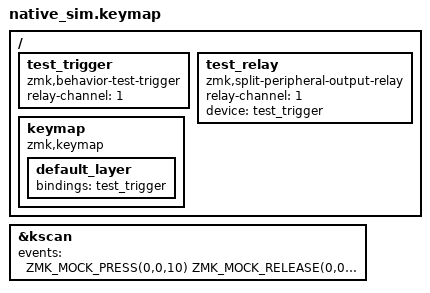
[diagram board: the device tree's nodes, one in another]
#include <dt-bindings/zmk/keys.h>
#include <behaviors.dtsi>
#include <dt-bindings/zmk/kscan_mock.h>

/ {
    test_trigger: test_trigger {
        compatible = "zmk,behavior-test-trigger";
        #binding-cells = <0>;
        relay-channel = <1>;
    };

    test_relay: test_relay {
        compatible = "zmk,split-peripheral-output-relay";
        relay-channel = <1>;
        device = <&test_trigger>; /* dummy reference */
    };

    keymap {
        compatible = "zmk,keymap";
        default_layer {
            bindings = <&test_trigger>;
        };
    };
};

&kscan {
    events = <
        ZMK_MOCK_PRESS(0,0,10)
        ZMK_MOCK_RELEASE(0,0,10)
    >;
};
